AUTOSAR XML (schema 4-0-3)
package /ComponentTypes
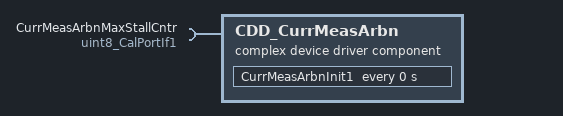
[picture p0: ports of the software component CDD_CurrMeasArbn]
  complex device driver sw component type CDD_CurrMeasArbn
    require port CurrMeasArbnMaxStallCntr: parameter-require-com-spec{init-value=20, parameter=Val}, required-interface=uint8_CalPortIf1
    behavior CDD_CurrMeasArbn_InternalBehavior: data-type-mapping=Nexteer
      ar-typed-per-instance-memorys:
        4 x data, all with sw-calibration-access=READ-ONLY, type=uint8:
          CurrMeasArbnSens0RollgCntPrev
          CurrMeasArbnSens0StallCntPrev
          CurrMeasArbnSens1RollgCntPrev
          CurrMeasArbnSens1StallCntPrev
      timing event CurrMeasCorrln_InitEvent: start-on-event=CurrMeasArbnInit1, period=0
      runnable CurrMeasArbnInit1
  swc implementation CDD_CurrMeasArbn_Implementation: behavior=CDD_CurrMeasArbn_InternalBehavior
    code-descriptors:
      code Default: artifact-descriptors=autosar-engineering-object={short-label=Default, category=SWSRC}
